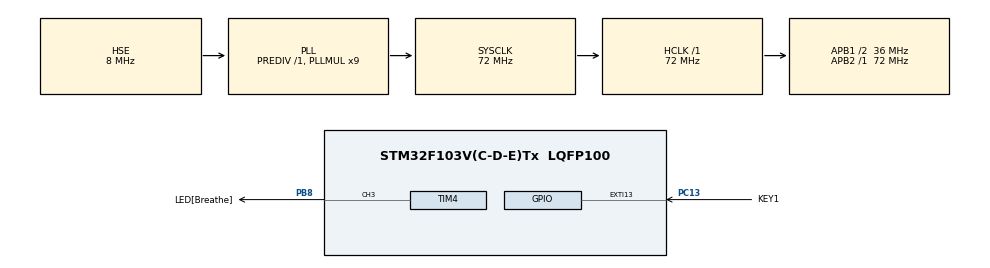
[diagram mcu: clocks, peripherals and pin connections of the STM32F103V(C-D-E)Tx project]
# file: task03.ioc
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Mcu.Family=STM32F1
Mcu.Name=STM32F103V(C-D-E)Tx
Mcu.Package=LQFP100
NVIC.EXTI15_10_IRQn=true\:3\:0\:true\:false\:true\:true\:true
NVIC.PriorityGroup=NVIC_PRIORITYGROUP_4
OSC_IN.Mode=HSE-External-Oscillator
OSC_IN.Signal=RCC_OSC_IN
OSC_OUT.Mode=HSE-External-Oscillator
OSC_OUT.Signal=RCC_OSC_OUT
PA13.Mode=Serial_Wire
PA13.Signal=SYS_JTMS-SWDIO
PA14.Mode=Serial_Wire
PA14.Signal=SYS_JTCK-SWCLK
PB8.GPIO_Label=LED[Breathe]
PB8.Signal=S_TIM4_CH3
PC13-TAMPER-RTC.GPIO_Label=KEY1
PC13-TAMPER-RTC.GPIO_ModeDefaultEXTI=GPIO_MODE_IT_FALLING
PC13-TAMPER-RTC.GPIO_PuPd=GPIO_PULLUP
PC13-TAMPER-RTC.Signal=GPXTI13
PC14-OSC32_IN.Mode=LSE-External-Oscillator
PC14-OSC32_IN.Signal=RCC_OSC32_IN
PC15-OSC32_OUT.Mode=LSE-External-Oscillator
PC15-OSC32_OUT.Signal=RCC_OSC32_OUT
ProjectManager.HeapSize=0x200
ProjectManager.StackSize=0x400
ProjectManager.TargetToolchain=MDK-ARM V5
RCC.AHBFreq_Value=72000000
RCC.APB1CLKDivider=RCC_HCLK_DIV2
RCC.APB1Freq_Value=36000000
RCC.APB1TimFreq_Value=72000000
RCC.APB2Freq_Value=72000000
RCC.APB2TimFreq_Value=72000000
RCC.HCLKFreq_Value=72000000
RCC.PLLMUL=RCC_PLL_MUL9
RCC.PLLSourceVirtual=RCC_PLLSOURCE_HSE
RCC.SYSCLKFreq_VALUE=72000000
RCC.SYSCLKSource=RCC_SYSCLKSOURCE_PLLCLK
RCC.USBFreq_Value=72000000
SH.S_TIM4_CH3.0=TIM4_CH3,PWM Generation3 CH3
TIM4.Channel-PWM\ Generation3\ CH3=TIM_CHANNEL_3
TIM4.OCPolarity_3=TIM_OCPOLARITY_LOW
TIM4.Period=99
TIM4.Prescaler=71
VP_TIM4_VS_ClockSourceINT.Mode=Internal
board=custom

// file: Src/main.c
/* USER CODE BEGIN Header */
/**
  ******************************************************************************
  * @file           : main.c
  * @brief          : Main program body
  ******************************************************************************
  * @attention
  *
  * <h2><center>&copy; Copyright (c) 2022 STMicroelectronics.
  * All rights reserved.</center></h2>
  *
  * This software component is licensed by ST under BSD 3-Clause license,
  * the "License"; You may not use this file except in compliance with the
  * License. You may obtain a copy of the License at:
  *                        opensource.org/licenses/BSD-3-Clause
  *
  ******************************************************************************
  */
/* USER CODE END Header */

#include "main.h"
#include "tim.h"
#include "gpio.h"

/* USER CODE BEGIN PV */
uint8_t keydown_flag = 0;
uint8_t pwm_value = 0;
uint8_t up_down_flag = 0;
/* USER CODE END PV */

void SystemClock_Config(void);

int main(void)
{

  /* MCU Configuration--------------------------------------------------------*/

  /* Reset of all peripherals, Initializes the Flash interface and the Systick. */
  HAL_Init();

  /* Configure the system clock */
  SystemClock_Config();

  /* Initialize all configured peripherals */
  MX_GPIO_Init();
  MX_TIM4_Init();
  /* USER CODE BEGIN 2 */
	HAL_TIM_PWM_Start(&htim4,TIM_CHANNEL_3);
  /* USER CODE END 2 */

  /* Infinite loop */
  while (1)
  {
		if(keydown_flag == 1){
			HAL_Delay(20);
			pwm_value==0?up_down_flag=0:0;
			pwm_value==50?up_down_flag=1:0;

			up_down_flag==0?pwm_value++:pwm_value--;

			__HAL_TIM_SET_COMPARE(&htim4,TIM_CHANNEL_3,pwm_value);
		}
		else{
		__HAL_TIM_SET_COMPARE(&htim4,TIM_CHANNEL_3,0);
		}
  }
}

void SystemClock_Config(void)
{
  RCC_OscInitTypeDef RCC_OscInitStruct = {0};
  RCC_ClkInitTypeDef RCC_ClkInitStruct = {0};

  /** Initializes the CPU, AHB and APB busses clocks
  */
  RCC_OscInitStruct.OscillatorType = RCC_OSCILLATORTYPE_HSE;
  RCC_OscInitStruct.HSEState = RCC_HSE_ON;
  RCC_OscInitStruct.HSEPredivValue = RCC_HSE_PREDIV_DIV1;
  RCC_OscInitStruct.HSIState = RCC_HSI_ON;
  RCC_OscInitStruct.PLL.PLLState = RCC_PLL_ON;
  RCC_OscInitStruct.PLL.PLLSource = RCC_PLLSOURCE_HSE;
  RCC_OscInitStruct.PLL.PLLMUL = RCC_PLL_MUL9;
  if (HAL_RCC_OscConfig(&RCC_OscInitStruct) != HAL_OK)
  {
    Error_Handler();
  }
  /** Initializes the CPU, AHB and APB busses clocks
  */
  RCC_ClkInitStruct.ClockType = RCC_CLOCKTYPE_HCLK|RCC_CLOCKTYPE_SYSCLK
                              |RCC_CLOCKTYPE_PCLK1|RCC_CLOCKTYPE_PCLK2;
  RCC_ClkInitStruct.SYSCLKSource = RCC_SYSCLKSOURCE_PLLCLK;
  RCC_ClkInitStruct.AHBCLKDivider = RCC_SYSCLK_DIV1;
  RCC_ClkInitStruct.APB1CLKDivider = RCC_HCLK_DIV2;
  RCC_ClkInitStruct.APB2CLKDivider = RCC_HCLK_DIV1;

  if (HAL_RCC_ClockConfig(&RCC_ClkInitStruct, FLASH_LATENCY_2) != HAL_OK)
  {
    Error_Handler();
  }
}

/* USER CODE BEGIN 4 */
void HAL_GPIO_EXTI_Callback(uint16_t GPIO_Pin){
	if(GPIO_Pin & GPIO_PIN_13){
		if(keydown_flag==0)
			keydown_flag = 1;
		else
			keydown_flag = 0;
		pwm_value = 0;
	}
}
/* USER CODE END 4 */

void Error_Handler(void)
{
}

/************************ (C) COPYRIGHT STMicroelectronics *****END OF FILE****/
